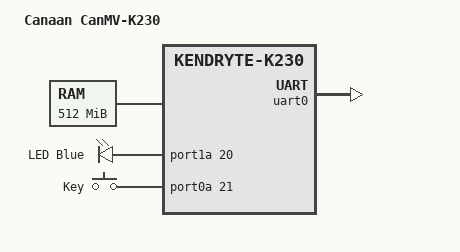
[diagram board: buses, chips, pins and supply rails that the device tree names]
// SPDX-License-Identifier: GPL-2.0 OR MIT
/*
 * Copyright (C) 2024 Yangyu Chen <cyy@cyyself.name>
 */
#include <dt-bindings/gpio/gpio.h>
#include <dt-bindings/input/input.h>
#include <dt-bindings/leds/common.h>

#include "k230.dtsi"

/ {
	model = "Canaan CanMV-K230";
	compatible = "canaan,canmv-k230", "canaan,kendryte-k230";

	chosen {
		stdout-path = "serial0:115200n8";
	};

	ddr: memory@0 {
		device_type = "memory";
		reg = <0x0 0x0 0x0 0x20000000>;
	};

	leds {
		compatible = "gpio-leds";

		led-0 {
			label = "LED Blue";
			gpios = <&port1a 20 GPIO_ACTIVE_HIGH>;
			default-state = "on";
		};
	};

	gpio-key {
		compatible = "gpio-keys";

		key-power {
			label = "Key";
			linux,code = <KEY_POWER>;
			gpios = <&port0a 21 GPIO_ACTIVE_HIGH>;
			linux,input-type = <EV_KEY>;
			debounce-interval = <100>;
		};
	};
};

&uart0 {
	status = "okay";
};
